# STM32L4A6 register map
File version: 1.0
CPU: CM4 r0p1, little endian, MPU, FPU, 4 interrupt priority bits
Registers are 32-bit, read-write, reset 0x0 unless marked. A register's access mark holds for its fields unless they carry their own. Offsets are from the block's base; [hi:lo] are bit positions; 'fields as' and 'values as' point back to an identical list.

## OTG_FS_GLOBAL — USB on the go full speed
Base 0x50000000
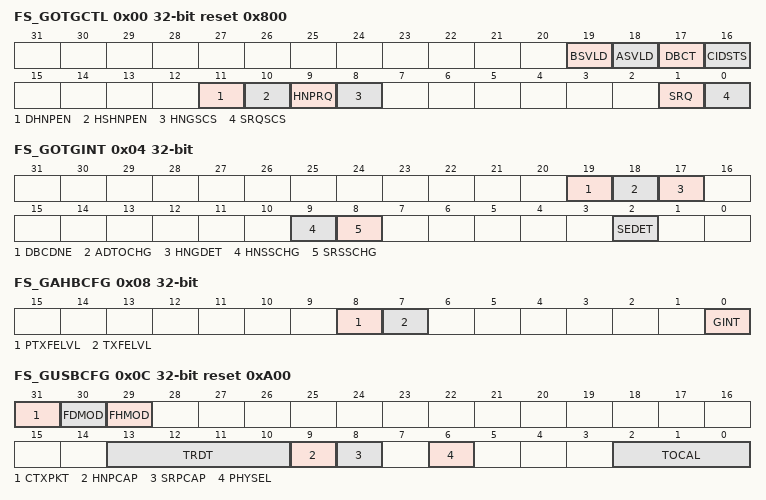
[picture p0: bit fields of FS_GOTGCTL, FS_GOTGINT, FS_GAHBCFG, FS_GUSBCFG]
0x00 FS_GOTGCTL access per field reset 0x800 — OTG_FS control and status register (OTG_FS_GOTGCTL)
  [19] BSVLD ro — B-session valid
  [18] ASVLD ro — A-session valid
  [17] DBCT ro — Long/short debounce time
  [16] CIDSTS ro — Connector ID status
  [11] DHNPEN rw — Device HNP enabled
  [10] HSHNPEN rw — Host set HNP enable
  [9] HNPRQ rw — HNP request
  [8] HNGSCS ro — Host negotiation success
  [1] SRQ rw — Session request
  [0] SRQSCS ro — Session request success
0x04 FS_GOTGINT — OTG_FS interrupt register (OTG_FS_GOTGINT)
  [19] DBCDNE — Debounce done
  [18] ADTOCHG — A-device timeout change
  [17] HNGDET — Host negotiation detected
  [9] HNSSCHG — Host negotiation success status change
  [8] SRSSCHG — Session request success status change
  [2] SEDET — Session end detected
0x08 FS_GAHBCFG — OTG_FS AHB configuration register (OTG_FS_GAHBCFG)
  [8] PTXFELVL — Periodic TxFIFO empty level
  [7] TXFELVL — TxFIFO empty level
  [0] GINT — Global interrupt mask
0x0C FS_GUSBCFG access per field reset 0xA00 — OTG_FS USB configuration register (OTG_FS_GUSBCFG)
  [31] CTXPKT rw — Corrupt Tx packet
  [30] FDMOD rw — Force device mode
  [29] FHMOD rw — Force host mode
  [13:10] TRDT rw — USB turnaround time
  [9] HNPCAP rw — HNP-capable
  [8] SRPCAP rw — SRP-capable
  [6] PHYSEL wo — Full Speed serial transceiver select
  [2:0] TOCAL rw — FS timeout calibration
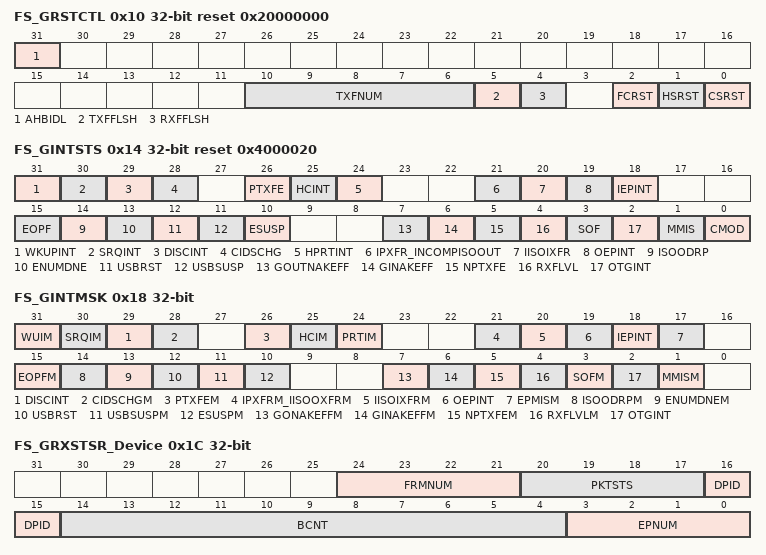
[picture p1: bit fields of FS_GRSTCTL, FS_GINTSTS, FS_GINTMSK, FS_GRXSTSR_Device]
0x10 FS_GRSTCTL access per field reset 0x20000000 — OTG_FS reset register (OTG_FS_GRSTCTL)
  [31] AHBIDL ro — AHB master idle
  [10:6] TXFNUM rw — TxFIFO number
  [5] TXFFLSH rw — TxFIFO flush
  [4] RXFFLSH rw — RxFIFO flush
  [2] FCRST rw — Host frame counter reset
  [1] HSRST rw — HCLK soft reset
  [0] CSRST rw — Core soft reset
0x14 FS_GINTSTS access per field reset 0x4000020 — OTG_FS core interrupt register (OTG_FS_GINTSTS)
  [31] WKUPINT rw — Resume/remote wakeup detected interrupt
  [30] SRQINT rw — Session request/new session detected interrupt
  [29] DISCINT rw — Disconnect detected interrupt
  [28] CIDSCHG rw — Connector ID status change
  [26] PTXFE ro — Periodic TxFIFO empty
  [25] HCINT ro — Host channels interrupt
  [24] HPRTINT ro — Host port interrupt
  [21] IPXFR_INCOMPISOOUT rw — Incomplete periodic transfer(Host mode)/Incomplete isochronous OUT transfer(Device mode)
  [20] IISOIXFR rw — Incomplete isochronous IN transfer
  [19] OEPINT ro — OUT endpoint interrupt
  [18] IEPINT ro — IN endpoint interrupt
  [15] EOPF rw — End of periodic frame interrupt
  [14] ISOODRP rw — Isochronous OUT packet dropped interrupt
  [13] ENUMDNE rw — Enumeration done
  [12] USBRST rw — USB reset
  [11] USBSUSP rw — USB suspend
  [10] ESUSP rw — Early suspend
  [7] GOUTNAKEFF ro — Global OUT NAK effective
  [6] GINAKEFF ro — Global IN non-periodic NAK effective
  [5] NPTXFE ro — Non-periodic TxFIFO empty
  [4] RXFLVL ro — RxFIFO non-empty
  [3] SOF rw — Start of frame
  [2] OTGINT ro — OTG interrupt
  [1] MMIS rw — Mode mismatch interrupt
  [0] CMOD ro — Current mode of operation
0x18 FS_GINTMSK access per field — OTG_FS interrupt mask register (OTG_FS_GINTMSK)
  [31] WUIM rw — Resume/remote wakeup detected interrupt mask
  [30] SRQIM rw — Session request/new session detected interrupt mask
  [29] DISCINT rw — Disconnect detected interrupt mask
  [28] CIDSCHGM rw — Connector ID status change mask
  [26] PTXFEM rw — Periodic TxFIFO empty mask
  [25] HCIM rw — Host channels interrupt mask
  [24] PRTIM ro — Host port interrupt mask
  [21] IPXFRM_IISOOXFRM rw — Incomplete periodic transfer mask(Host mode)/Incomplete isochronous OUT transfer mask(Device mode)
  [20] IISOIXFRM rw — Incomplete isochronous IN transfer mask
  [19] OEPINT rw — OUT endpoints interrupt mask
  [18] IEPINT rw — IN endpoints interrupt mask
  [17] EPMISM rw — Endpoint mismatch interrupt mask
  [15] EOPFM rw — End of periodic frame interrupt mask
  [14] ISOODRPM rw — Isochronous OUT packet dropped interrupt mask
  [13] ENUMDNEM rw — Enumeration done mask
  [12] USBRST rw — USB reset mask
  [11] USBSUSPM rw — USB suspend mask
  [10] ESUSPM rw — Early suspend mask
  [7] GONAKEFFM rw — Global OUT NAK effective mask
  [6] GINAKEFFM rw — Global non-periodic IN NAK effective mask
  [5] NPTXFEM rw — Non-periodic TxFIFO empty mask
  [4] RXFLVLM rw — Receive FIFO non-empty mask
  [3] SOFM rw — Start of frame mask
  [2] OTGINT rw — OTG interrupt mask
  [1] MMISM rw — Mode mismatch interrupt mask
0x1C FS_GRXSTSR_Device ro — OTG_FS Receive status debug read(Device mode)
  [24:21] FRMNUM — Frame number
  [20:17] PKTSTS — Packet status
  [16:15] DPID — Data PID
  [14:4] BCNT — Byte count
  [3:0] EPNUM — Endpoint number
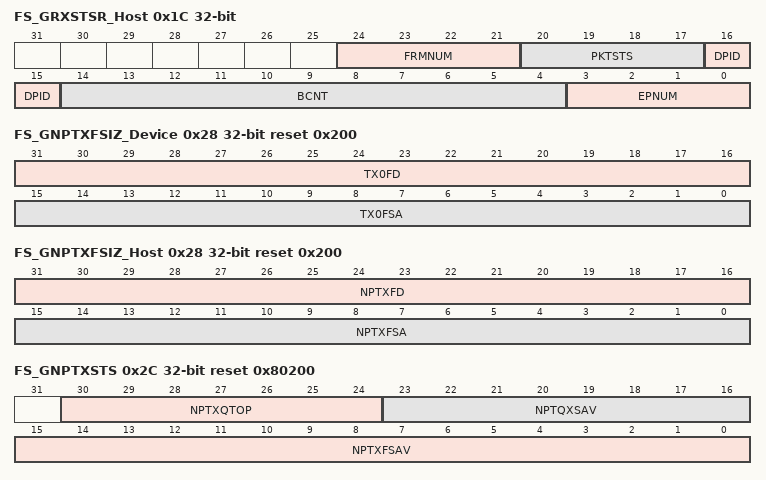
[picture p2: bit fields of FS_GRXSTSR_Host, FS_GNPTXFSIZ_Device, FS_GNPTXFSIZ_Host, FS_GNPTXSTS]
0x1C FS_GRXSTSR_Host ro (alternate view of FS_GRXSTSR_Device) — OTG_FS Receive status debug read(Host mode)
  fields as FS_GRXSTSR_Device
0x24 FS_GRXFSIZ reset 0x200 — OTG_FS Receive FIFO size register (OTG_FS_GRXFSIZ)
  [15:0] RXFD — RxFIFO depth
0x28 FS_GNPTXFSIZ_Device reset 0x200 — OTG_FS non-periodic transmit FIFO size register (Device mode)
  [31:16] TX0FD — Endpoint 0 TxFIFO depth
  [15:0] TX0FSA — Endpoint 0 transmit RAM start address
0x28 FS_GNPTXFSIZ_Host reset 0x200 (alternate view of FS_GNPTXFSIZ_Device) — OTG_FS non-periodic transmit FIFO size register (Host mode)
  [31:16] NPTXFD — Non-periodic TxFIFO depth
  [15:0] NPTXFSA — Non-periodic transmit RAM start address
0x2C FS_GNPTXSTS ro reset 0x80200 — OTG_FS non-periodic transmit FIFO/queue status register (OTG_FS_GNPTXSTS)
  [30:24] NPTXQTOP — Top of the non-periodic transmit request queue
  [23:16] NPTQXSAV — Non-periodic transmit request queue space available
  [15:0] NPTXFSAV — Non-periodic TxFIFO space available
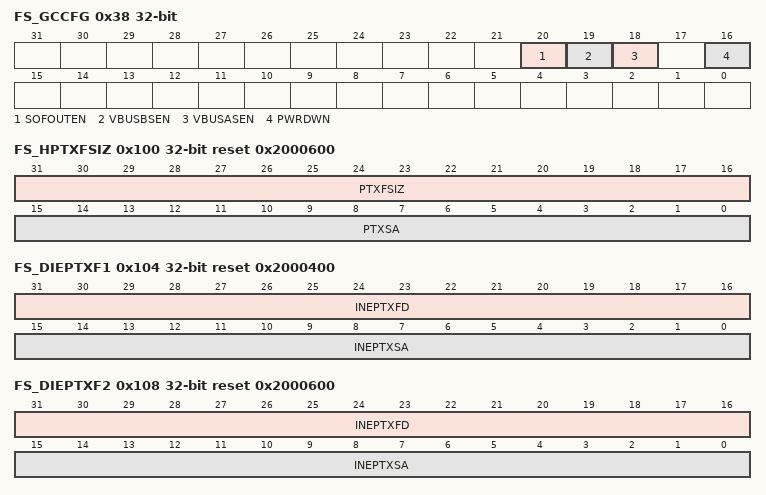
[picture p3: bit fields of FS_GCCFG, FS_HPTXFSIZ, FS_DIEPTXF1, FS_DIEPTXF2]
0x38 FS_GCCFG — OTG_FS general core configuration register (OTG_FS_GCCFG)
  [20] SOFOUTEN — SOF output enable
  [19] VBUSBSEN — Enable the VBUS sensing device
  [18] VBUSASEN — Enable the VBUS sensing device
  [16] PWRDWN — Power down
0x3C FS_CID reset 0x1000 — core ID register
  [31:0] PRODUCT_ID
0x100 FS_HPTXFSIZ reset 0x2000600 — OTG_FS Host periodic transmit FIFO size register (OTG_FS_HPTXFSIZ)
  [31:16] PTXFSIZ — Host periodic TxFIFO depth
  [15:0] PTXSA — Host periodic TxFIFO start address
0x104 FS_DIEPTXF1 reset 0x2000400 — OTG_FS device IN endpoint transmit FIFO size register (OTG_FS_DIEPTXF2)
  [31:16] INEPTXFD — IN endpoint TxFIFO depth
  [15:0] INEPTXSA — IN endpoint FIFO2 transmit RAM start address
0x108 FS_DIEPTXF2 reset 0x2000600 — OTG_FS device IN endpoint transmit FIFO size register (OTG_FS_DIEPTXF3)
  [31:16] INEPTXFD — IN endpoint TxFIFO depth
  [15:0] INEPTXSA — IN endpoint FIFO3 transmit RAM start address
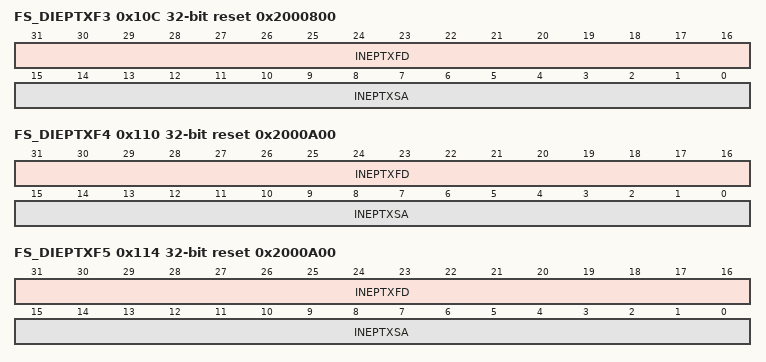
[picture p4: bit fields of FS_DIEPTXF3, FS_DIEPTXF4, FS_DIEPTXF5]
0x10C FS_DIEPTXF3 reset 0x2000800 — OTG_FS device IN endpoint transmit FIFO size register (OTG_FS_DIEPTXF4)
  [31:16] INEPTXFD — IN endpoint TxFIFO depth
  [15:0] INEPTXSA — IN endpoint FIFO4 transmit RAM start address
0x110 FS_DIEPTXF4 reset 0x2000A00 — OTG_FS device IN endpoint transmit FIFO size register (OTG_FS_DIEPTXF4)
  fields as FS_DIEPTXF3
0x114 FS_DIEPTXF5 reset 0x2000A00 — OTG_FS device IN endpoint transmit FIFO size register (OTG_FS_DIEPTXF5)
  fields as FS_DIEPTXF3
